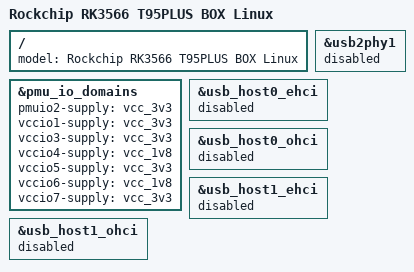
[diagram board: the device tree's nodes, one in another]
#include "rk3566-box-demo-v10.dtsi"
#include "rk3568-linux.dtsi"

/ {
    model = "Rockchip RK3566 T95PLUS BOX Linux";
};

&pmu_io_domains {
    status = "okay";
    pmuio2-supply = <&vcc_3v3>;
    vccio1-supply = <&vcc_3v3>;
    vccio3-supply = <&vcc_3v3>;
    vccio4-supply = <&vcc_1v8>;
    vccio5-supply = <&vcc_3v3>;
    vccio6-supply = <&vcc_1v8>;
    vccio7-supply = <&vcc_3v3>;
};

&usb2phy1 {
    status = "disabled";
};

&usb_host0_ehci {
    status = "disabled";
};

&usb_host0_ohci {
    status = "disabled";
};

&usb_host1_ehci {
    status = "disabled";
};

&usb_host1_ohci {
    status = "disabled";
};
